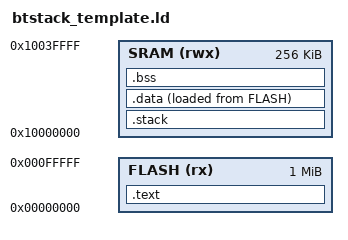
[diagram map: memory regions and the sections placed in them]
/******************************************************************************
 *
 * hello_world_uart.ld - Linker script for applications using startup_gnu.c
 *
 *****************************************************************************/
ENTRY(am_reset_isr)

MEMORY
{
    FLASH (rx) : ORIGIN = 0x00000000, LENGTH = 1024K
    SRAM (rwx) : ORIGIN = 0x10000000, LENGTH = 256K
}

SECTIONS
{
    .text :
    {
        . = ALIGN(4);
        KEEP(*(.isr_vector))
        *(.text)
        *(.text*)
        *(.rodata)
        *(.rodata*)
        . = ALIGN(4);
        _etext = .;
    } > FLASH

  /* User stack section initialized by startup code. */
  .stack (NOLOAD):
    {
        . = ALIGN(8);
        *(.stack)
        *(.stack*)
        . = ALIGN(8);
    } > SRAM

    .data :
    {
        . = ALIGN(4);
        _sdata = .;
        *(.data)
        *(.data*)
        . = ALIGN(4);
        _edata = .;
    } > SRAM AT>FLASH

    /* used by startup to initialize data */
    _init_data = LOADADDR(.data);

    .bss :
    {
        . = ALIGN(4);
        _sbss = .;
        *(.bss)
        *(.bss*)
        *(COMMON)
        . = ALIGN(4);
        _ebss = .;
    } > SRAM

  .ARM.attributes 0 : { *(.ARM.attributes) }
}


